VERSION ""

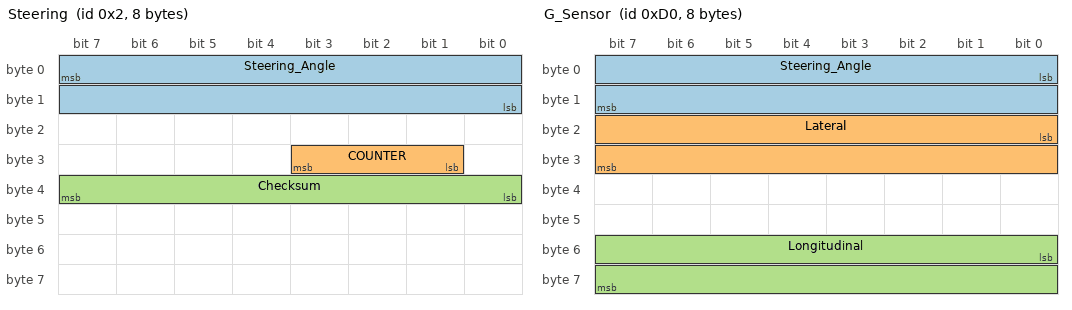
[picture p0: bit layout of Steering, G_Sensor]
BO_ 2 Steering: 8 XXX
 SG_ Steering_Angle : 7|16@0- (0.1,0) [-500|500] "degree" XXX
 SG_ COUNTER : 27|3@0+ (1,0) [0|7] "" XXX
 SG_ Checksum : 39|8@0+ (1,0) [0|255] "" XXX

BO_ 208 G_Sensor: 8 XXX
 SG_ Steering_Angle : 0|16@1- (-0.1,0) [-500|500] "" XXX
 SG_ Lateral : 16|16@1- (-0.0035,1) [-255|255] "" XXX
 SG_ Longitudinal : 48|16@1- (-0.00035,0) [-255|255] "" XXX

BO_ 209 Brake_Pedal: 8 XXX
 SG_ Speed : 0|16@1+ (0.05625,0) [0|255] "KPH" XXX
 SG_ Brake_Pedal : 16|8@1+ (1,0) [0|255] "" XXX

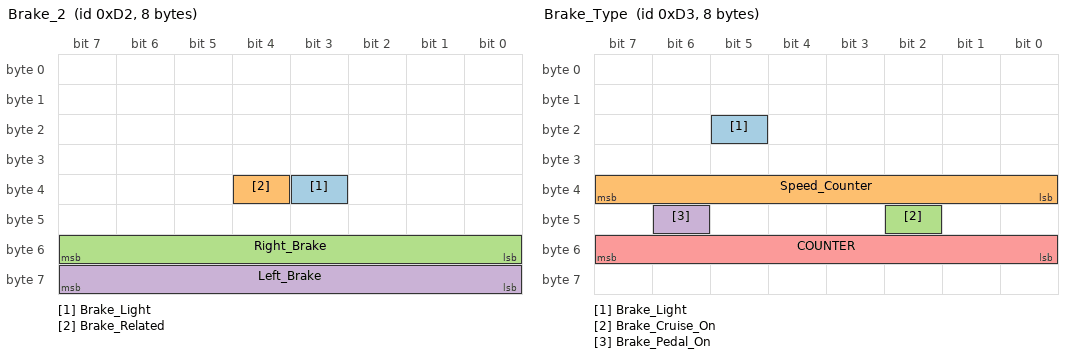
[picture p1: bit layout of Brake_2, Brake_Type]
BO_ 210 Brake_2: 8 XXX
 SG_ Brake_Light : 35|1@1+ (1,0) [0|1] "" XXX
 SG_ Brake_Related : 36|1@1+ (1,0) [0|1] "" XXX
 SG_ Right_Brake : 48|8@1+ (1,0) [0|255] "" XXX
 SG_ Left_Brake : 56|8@1+ (1,0) [0|255] "" XXX

BO_ 211 Brake_Type: 8 XXX
 SG_ Brake_Light : 21|1@1+ (1,0) [0|1] "" XXX
 SG_ Speed_Counter : 32|8@1+ (1,0) [0|255] "" XXX
 SG_ Brake_Cruise_On : 42|1@1+ (1,0) [0|1] "" XXX
 SG_ Brake_Pedal_On : 46|1@1+ (1,0) [0|1] "" XXX
 SG_ COUNTER : 48|8@1+ (1,0) [0|255] "" XXX

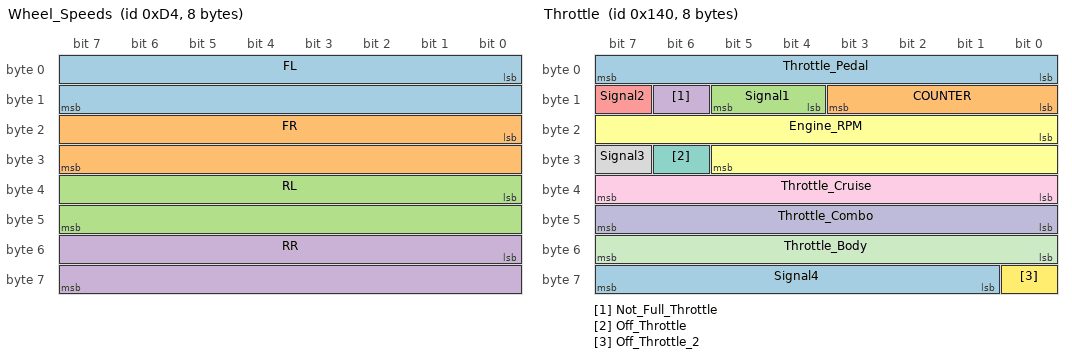
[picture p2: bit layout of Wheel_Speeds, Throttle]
BO_ 212 Wheel_Speeds: 8 XXX
 SG_ FL : 0|16@1+ (0.0592,0) [0|255] "KPH" XXX
 SG_ FR : 16|16@1+ (0.0592,0) [0|255] "KPH" XXX
 SG_ RL : 32|16@1+ (0.0592,0) [0|255] "KPH" XXX
 SG_ RR : 48|16@1+ (0.0592,0) [0|255] "KPH" XXX

BO_ 320 Throttle: 8 XXX
 SG_ Throttle_Pedal : 0|8@1+ (0.392157,0) [0|255] "" XXX
 SG_ COUNTER : 8|4@1+ (1,0) [0|15] "" XXX
 SG_ Signal1 : 12|2@1+ (1,0) [0|7] "" XXX
 SG_ Not_Full_Throttle : 14|1@1+ (1,0) [0|1] "" XXX
 SG_ Signal2 : 15|1@1+ (1,0) [0|1] "" XXX
 SG_ Engine_RPM : 16|14@1+ (1,0) [0|32767] "" XXX
 SG_ Off_Throttle : 30|1@1+ (1,0) [0|1] "" XXX
 SG_ Signal3 : 31|1@1+ (1,0) [0|1] "" XXX
 SG_ Throttle_Cruise : 32|8@1+ (1,0) [0|255] "" XXX
 SG_ Throttle_Combo : 40|8@1+ (1,0) [0|255] "" XXX
 SG_ Throttle_Body : 48|8@1+ (1,0) [0|255] "" XXX
 SG_ Off_Throttle_2 : 56|1@1+ (1,0) [0|1] "" XXX
 SG_ Signal4 : 57|7@1+ (1,0) [0|127] "" XXX

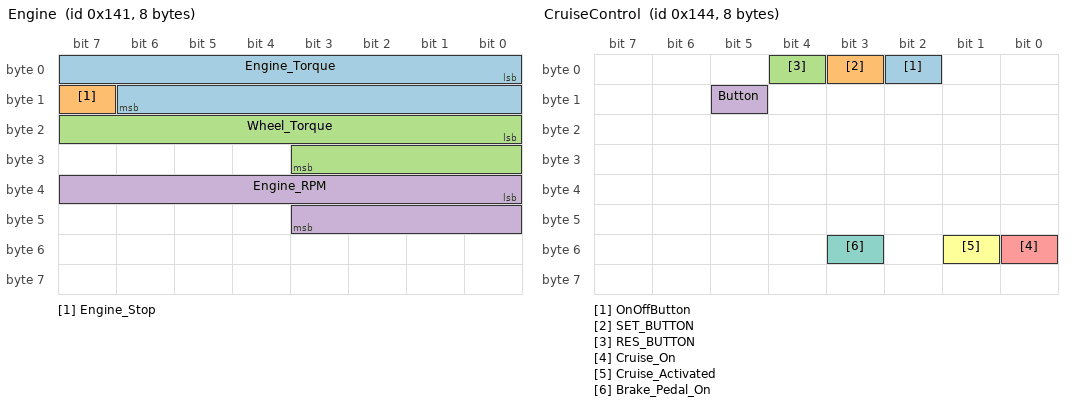
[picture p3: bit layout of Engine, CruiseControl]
BO_ 321 Engine: 8 XXX
 SG_ Engine_Torque : 0|15@1+ (1,0) [0|255] "" XXX
 SG_ Engine_Stop : 15|1@1+ (1,0) [0|1] "" XXX
 SG_ Wheel_Torque : 16|12@1+ (1,0) [0|4095] "" XXX
 SG_ Engine_RPM : 32|12@1+ (1,0) [0|8191] "" XXX

BO_ 324 CruiseControl: 8 XXX
 SG_ OnOffButton : 2|1@1+ (1,0) [0|1] "" XXX
 SG_ SET_BUTTON : 3|1@1+ (1,0) [0|1] "" XXX
 SG_ RES_BUTTON : 4|1@1+ (1,0) [0|1] "" XXX
 SG_ Button : 13|1@1+ (1,0) [0|1] "" XXX
 SG_ Cruise_On : 48|1@1+ (1,0) [0|1] "" XXX
 SG_ Cruise_Activated : 49|1@1+ (1,0) [0|1] "" XXX
 SG_ Brake_Pedal_On : 51|1@1+ (1,0) [0|1] "" XXX

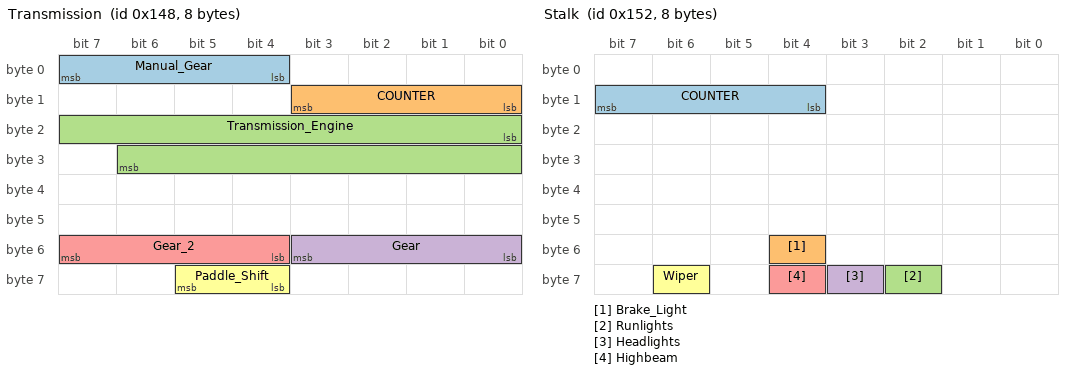
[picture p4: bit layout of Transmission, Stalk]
BO_ 328 Transmission: 8 XXX
 SG_ Manual_Gear : 4|4@1+ (1,0) [0|15] "" XXX
 SG_ COUNTER : 8|4@1+ (1,0) [0|15] "" XXX
 SG_ Transmission_Engine : 16|15@1+ (1,0) [0|65535] "" XXX
 SG_ Gear : 48|4@1+ (1,0) [0|15] "" XXX
 SG_ Gear_2 : 52|4@1+ (1,0) [0|15] "" XXX
 SG_ Paddle_Shift : 60|2@1+ (1,0) [0|3] "" XXX

BO_ 329 CVT_Ratio: 8 XXX

BO_ 336 Brake_Pressure: 8 XXX
 SG_ Brake_Pressure_Right : 0|8@1+ (1,0) [0|255] "" XXX
 SG_ Brake_Pressure_Left : 8|8@1+ (1,0) [0|255] "" XXX

BO_ 338 Stalk: 8 XXX
 SG_ COUNTER : 12|4@1+ (1,0) [0|15] "" XXX
 SG_ Brake_Light : 52|1@1+ (1,0) [0|1] "" XXX
 SG_ Runlights : 58|1@1+ (1,0) [0|1] "" XXX
 SG_ Headlights : 59|1@1+ (1,0) [0|1] "" XXX
 SG_ Highbeam : 60|1@1+ (1,0) [0|1] "" XXX
 SG_ Wiper : 62|1@1+ (1,0) [0|1] "" XXX

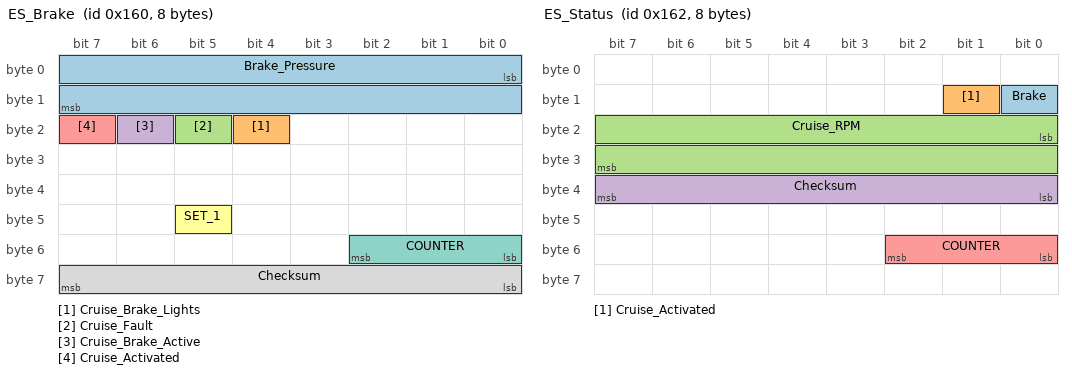
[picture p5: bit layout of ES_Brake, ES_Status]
BO_ 352 ES_Brake: 8 XXX
 SG_ Brake_Pressure : 0|16@1+ (1,0) [0|255] "" XXX
 SG_ Cruise_Brake_Lights : 20|1@1+ (1,0) [0|1] "" XXX
 SG_ Cruise_Fault : 21|1@1+ (1,0) [0|1] "" XXX
 SG_ Cruise_Brake_Active : 22|1@1+ (1,0) [0|1] "" XXX
 SG_ Cruise_Activated : 23|1@1+ (1,0) [0|1] "" XXX
 SG_ SET_1 : 45|1@0+ (1,0) [0|1] "" XXX
 SG_ COUNTER : 48|3@1+ (1,0) [0|7] "" XXX
 SG_ Checksum : 56|8@1+ (1,0) [0|255] "" XXX

BO_ 353 ES_Distance: 8 XXX
 SG_ Cruise_Throttle : 0|12@1+ (1,0) [0|4095] "" XXX
 SG_ Signal1 : 12|4@1+ (1,0) [0|15] "" XXX
 SG_ Car_Follow : 16|1@1+ (1,0) [0|1] "" XXX
 SG_ Signal2 : 17|3@1+ (1,0) [0|7] "" XXX
 SG_ Cruise_Brake_Active : 20|1@1+ (1,0) [0|1] "" XXX
 SG_ Distance_Swap : 21|1@1+ (1,0) [0|1] "" XXX
 SG_ Standstill : 22|1@1+ (1,0) [0|1] "" XXX
 SG_ Signal3 : 23|1@1+ (1,0) [0|1] "" XXX
 SG_ Close_Distance : 24|8@1+ (0.019607,0) [0|5] "m" XXX
 SG_ Signal4 : 32|9@1+ (1,0) [0|255] "" XXX
 SG_ Standstill_2 : 41|1@1+ (1,0) [0|1] "" XXX
 SG_ Cruise_Fault : 42|1@1+ (1,0) [0|1] "" XXX
 SG_ Signal5 : 43|1@1+ (1,0) [0|1] "" XXX
 SG_ COUNTER : 44|3@1+ (1,0) [0|7] "" XXX
 SG_ Signal6 : 47|1@1+ (1,0) [0|1] "" XXX
 SG_ Cruise_Button : 48|3@1+ (1,0) [0|7] "" XXX
 SG_ Signal7 : 51|5@1+ (1,0) [0|31] "" XXX
 SG_ Checksum : 56|8@1+ (1,0) [0|255] "" XXX

BO_ 354 ES_Status: 8 XXX
 SG_ Brake : 8|1@1+ (1,0) [0|1] "" XXX
 SG_ Cruise_Activated : 9|1@1+ (1,0) [0|1] "" XXX
 SG_ Cruise_RPM : 16|16@1+ (1,0) [0|65535] "" XXX
 SG_ Checksum : 32|8@1+ (1,0) [0|255] "" XXX
 SG_ COUNTER : 48|3@1+ (1,0) [0|7] "" XXX

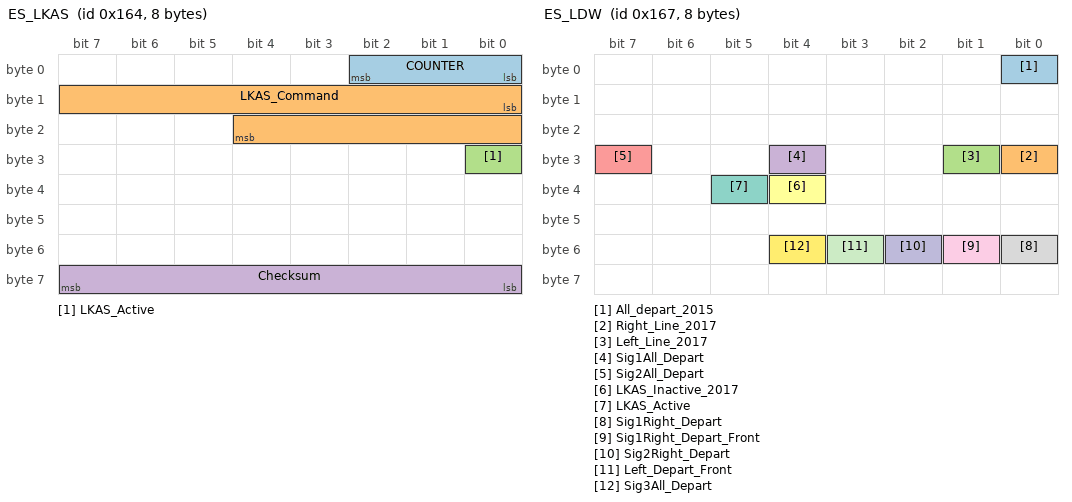
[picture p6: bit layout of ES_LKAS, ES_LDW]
BO_ 356 ES_LKAS: 8 XXX
 SG_ COUNTER : 0|3@1+ (1,0) [0|7] "" XXX
 SG_ LKAS_Command : 8|13@1- (-1,0) [-4096|4096] "" XXX
 SG_ LKAS_Active : 24|1@1+ (1,0) [0|1] "" XXX
 SG_ Checksum : 56|8@1+ (1,0) [0|255] "" XXX

BO_ 359 ES_LDW: 8 XXX
 SG_ All_depart_2015 : 0|1@1+ (1,0) [0|1] "" XXX
 SG_ Right_Line_2017 : 24|1@1+ (1,0) [0|1] "" XXX
 SG_ Left_Line_2017 : 25|1@1+ (1,0) [0|1] "" XXX
 SG_ Sig1All_Depart : 28|1@1+ (1,0) [0|1] "" XXX
 SG_ Sig2All_Depart : 31|1@1+ (1,0) [0|1] "" XXX
 SG_ LKAS_Inactive_2017 : 36|1@1+ (1,0) [0|1] "" XXX
 SG_ LKAS_Active : 37|1@1+ (1,0) [0|1] "" XXX
 SG_ Sig1Right_Depart : 48|1@1+ (1,0) [0|1] "" XXX
 SG_ Sig1Right_Depart_Front : 49|1@1+ (1,0) [0|1] "" XXX
 SG_ Sig2Right_Depart : 50|1@1+ (1,0) [0|1] "" XXX
 SG_ Left_Depart_Front : 51|1@1+ (1,0) [0|1] "" XXX
 SG_ Sig3All_Depart : 52|1@1+ (1,0) [0|1] "" XXX

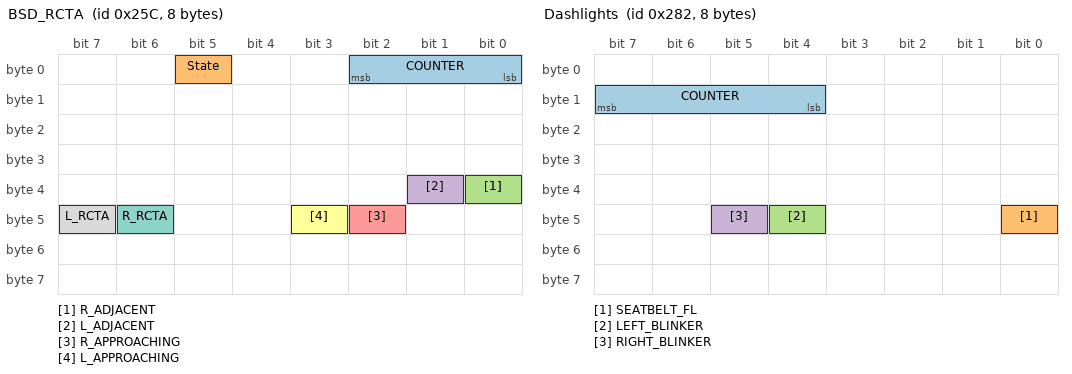
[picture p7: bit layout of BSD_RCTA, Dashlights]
BO_ 604 BSD_RCTA: 8 XXX
 SG_ COUNTER : 0|3@1+ (1,0) [0|7] "" XXX
 SG_ State : 5|1@1+ (1,0) [0|1] "" XXX
 SG_ R_ADJACENT : 32|1@1+ (1,0) [0|1] "" XXX
 SG_ L_ADJACENT : 33|1@1+ (1,0) [0|1] "" XXX
 SG_ R_APPROACHING : 42|1@1+ (1,0) [0|1] "" XXX
 SG_ L_APPROACHING : 43|1@1+ (1,0) [0|1] "" XXX
 SG_ R_RCTA : 46|1@1+ (1,0) [0|1] "" XXX
 SG_ L_RCTA : 47|1@1+ (1,0) [0|1] "" XXX

BO_ 642 Dashlights: 8 XXX
 SG_ COUNTER : 12|4@1+ (1,0) [0|15] "" XXX
 SG_ SEATBELT_FL : 40|1@1+ (1,0) [0|1] "" XXX
 SG_ LEFT_BLINKER : 44|1@1+ (1,0) [0|1] "" XXX
 SG_ RIGHT_BLINKER : 45|1@1+ (1,0) [0|1] "" XXX

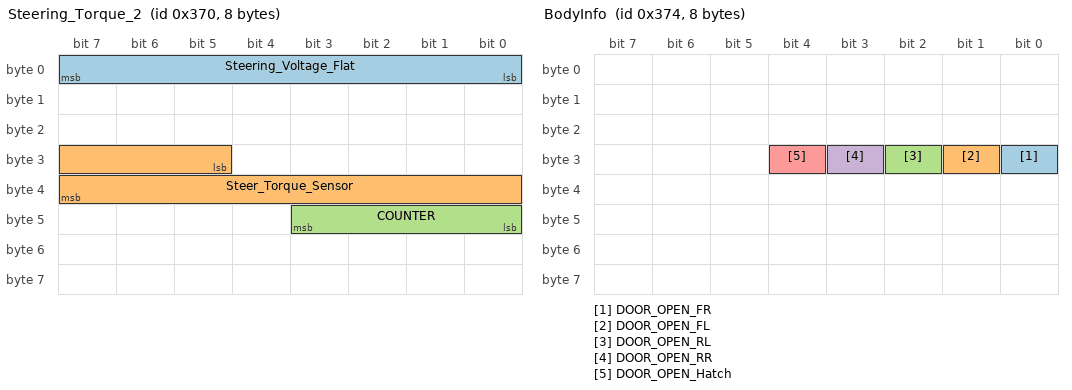
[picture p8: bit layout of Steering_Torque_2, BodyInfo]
BO_ 880 Steering_Torque_2: 8 XXX
 SG_ Steering_Voltage_Flat : 0|8@1+ (1,0) [0|255] "" XXX
 SG_ Steer_Torque_Sensor : 29|11@1- (-1,0) [-1000|1000] "" XXX
 SG_ COUNTER : 40|4@1+ (1,0) [0|15] "" XXX

BO_ 884 BodyInfo: 8 XXX
 SG_ DOOR_OPEN_FR : 24|1@1+ (1,0) [0|1] "" XXX
 SG_ DOOR_OPEN_FL : 25|1@1+ (1,0) [0|1] "" XXX
 SG_ DOOR_OPEN_RL : 26|1@1+ (1,0) [0|1] "" XXX
 SG_ DOOR_OPEN_RR : 27|1@1+ (1,0) [0|1] "" XXX
 SG_ DOOR_OPEN_Hatch : 28|1@1+ (1,0) [0|1] "" XXX

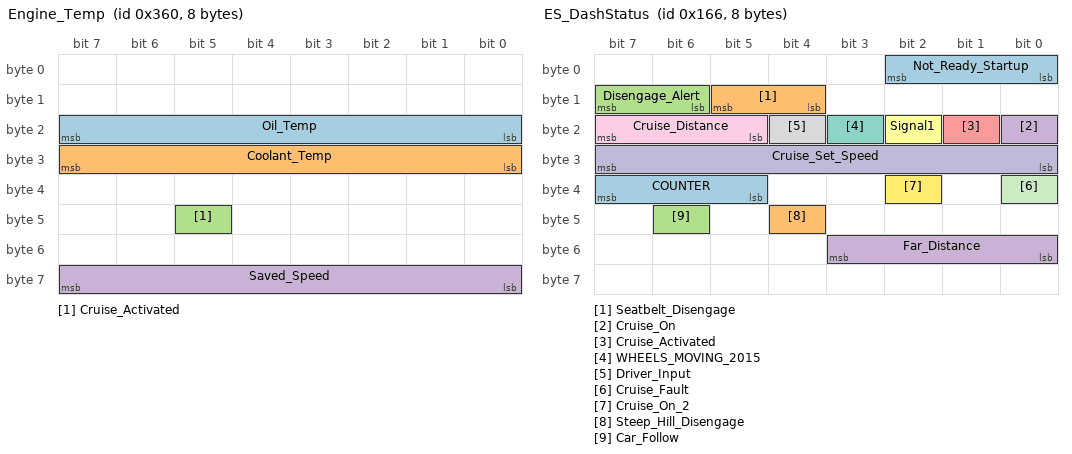
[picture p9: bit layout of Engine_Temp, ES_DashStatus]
BO_ 864 Engine_Temp: 8 XXX
 SG_ Oil_Temp : 16|8@1+ (1,-40) [0|255] "" XXX
 SG_ Coolant_Temp : 24|8@1+ (1,-40) [0|255] "" XXX
 SG_ Cruise_Activated : 45|1@1+ (1,0) [0|1] "" XXX
 SG_ Saved_Speed : 56|8@1+ (1,0) [0|255] "" XXX

BO_ 866 Fuel: 8 XXX

BO_ 977 Dash_State2: 8 XXX
 SG_ UNITS : 15|1@1+ (1,0) [0|1] "" XXX

BO_ 1745 Dash_State: 8 XXX
 SG_ Units : 15|1@1+ (1,0) [0|1] "" XXX

BO_ 358 ES_DashStatus: 8 XXX
 SG_ Not_Ready_Startup : 0|3@1+ (1,0) [0|7] "" XXX
 SG_ Seatbelt_Disengage : 12|2@1+ (1,0) [0|3] "" XXX
 SG_ Disengage_Alert : 14|2@1+ (1,0) [0|3] "" XXX
 SG_ Cruise_On : 16|1@1+ (1,0) [0|1] "" XXX
 SG_ Cruise_Activated : 17|1@1+ (1,0) [0|1] "" XXX
 SG_ Signal1 : 18|1@1+ (1,0) [0|1] "" XXX
 SG_ WHEELS_MOVING_2015 : 19|1@1+ (1,0) [0|1] "" XXX
 SG_ Driver_Input : 20|1@1+ (1,0) [0|1] "" XXX
 SG_ Cruise_Distance : 21|3@1+ (1,0) [0|7] "" XXX
 SG_ Cruise_Set_Speed : 24|8@1+ (1,0) [0|255] "" XXX
 SG_ Cruise_Fault : 32|1@1+ (1,0) [0|1] "" XXX
 SG_ Cruise_On_2 : 34|1@1+ (1,0) [0|1] "" XXX
 SG_ COUNTER : 37|3@1+ (1,0) [0|7] "" XXX
 SG_ Steep_Hill_Disengage : 44|1@1+ (1,0) [0|3] "" XXX
 SG_ Car_Follow : 46|1@1+ (1,0) [0|1] "" XXX
 SG_ Far_Distance : 48|4@1+ (5,0) [0|75] "m" XXX

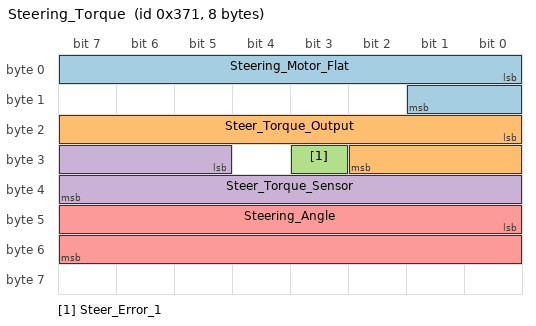
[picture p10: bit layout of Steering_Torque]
BO_ 881 Steering_Torque: 8 XXX
 SG_ Steering_Motor_Flat : 0|10@1+ (32,0) [0|1000] "" XXX
 SG_ Steer_Torque_Output : 16|11@1- (-32,0) [-1000|1000] "" XXX
 SG_ Steer_Error_1 : 27|1@1+ (1,0) [0|1] "" XXX
 SG_ Steer_Torque_Sensor : 29|11@1- (1,0) [-1000|1000] "" XXX
 SG_ Steering_Angle : 40|16@1- (-0.033,0) [-600|600] "" XXX

BU_: CLOCK HUD H_U DATC CCP KMA_TMU CUBIS TMU IPM RSE_R RRC CGW RSE_L AMP EDT SWRC IBOX CLU FHCU ASD MON AVM KBD

CM_ 272 "Alternative LKAS message, used on cars such as 2023 Ioniq 6, 2nd gen Kona. Matches LKAS except size is 32 bytes";
CM_ 676 "Contains signals with detailed lane line information. Used by ADAS ECU on HDA 2 vehicles to operate LFA.";
CM_ 866 "Contains signals with detailed lane line information. Used by ADAS ECU on HDA 2 vehicles to operate LFA. Used on cars that use message 272.";
CM_ 1043 "Lamp signals do not seem universal on cars that use LKAS_ALT, but stalk signals do.";

CM_ SG_ 80 HAS_LANE_SAFETY "If 0, hides LKAS 'Lane Safety' menu from vehicle settings";
CM_ SG_ 96 BRAKE_PRESSURE "User applied brake pedal pressure. Ramps from computer applied pressure on falling edge of cruise. Cruise cancels if !=0";
CM_ SG_ 101 BRAKE_POSITION "User applied brake pedal position, max is ~700. Signed on some vehicles";
CM_ SG_ 373 PROBABLY_EQUIP "aeb equip?";
CM_ SG_ 373 ACCEnable "Likely a copy of CAN's TCS13->ACCEnable";
CM_ SG_ 373 DriverBraking "Likely derived from BRAKE->BRAKE_POSITION";
CM_ SG_ 373 DriverBrakingLowSens "Higher threshold version of DriverBraking";
CM_ SG_ 352 SET_ME_9 "has something to do with AEB settings";
CM_ SG_ 416 VSetDis "set speed in display units";
CM_ SG_ 676 LEFT_LANE_LINE "Left lane line confidence";
CM_ SG_ 676 RIGHT_LANE_LINE "Right lane line confidence";
CM_ SG_ 736 MAX_SPEED "Display units. Restricts car from driving above this speed unless accelerator pedal is depressed beyond pressure point";
CM_ SG_ 866 LEFT_LANE_LINE "Left lane line confidence";
CM_ SG_ 866 RIGHT_LANE_LINE "Right lane line confidence";
CM_ SG_ 961 COUNTER_ALT "only increments on change";
CM_ SG_ 1041 COUNTER_ALT "only increments on change";
CM_ SG_ 1043 COUNTER_ALT "only increments on change";
CM_ SG_ 1043 USE_ALT_LAMP "likely 1 on cars that use alt lamp signals";
